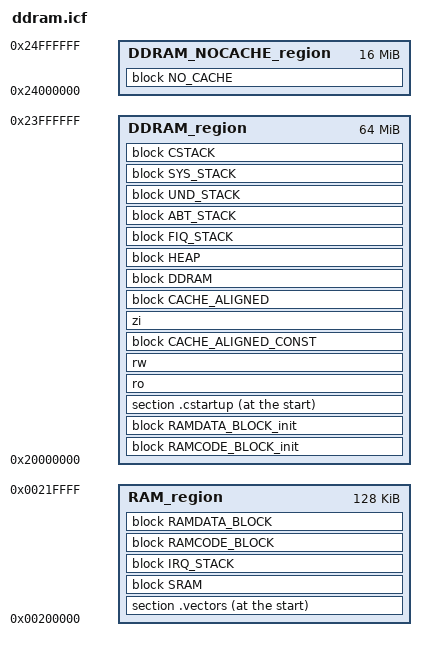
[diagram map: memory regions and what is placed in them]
define memory mem with size = 4G;
define region RAM_region           = mem:[from 0x00200000 to 0x0021FFFF];
define region DDRAM_region         = mem:[from 0x20000000 to 0x23FFFFFF];
define region DDRAM_NOCACHE_region = mem:[from 0x24000000 to 0x24FFFFFF];

define block CSTACK    with alignment = 8, size = 0x800 { };
define block IRQ_STACK with alignment = 8, size = 0x60  { };
define block FIQ_STACK with alignment = 8, size = 0x60  { };
define block ABT_STACK with alignment = 8, size = 0x40  { };
define block UND_STACK with alignment = 8, size = 0x40  { };
define block SYS_STACK with alignment = 8, size = 0x40  { };
define block HEAP      with alignment = 4, size = 0x200 { };

define block SRAM { section .region_sram  };
define block DDRAM { section .region_ddr };

define block RAMCODE_BLOCK      { section .ramcode_section };
define block RAMCODE_BLOCK_init { section .ramcode_section_init };
define block RAMDATA_BLOCK      { section .ramdata_section };
define block RAMDATA_BLOCK_init { section .ramdata_section_init };

/* Please see drivers/mm/cache.h for details on the "Cache-aligned" sections */
define block NO_CACHE { section .region_nocache };
define block CACHE_ALIGNED with alignment = 32 { section .region_cache_aligned };
define block CACHE_ALIGNED_CONST with alignment = 32 { section .region_cache_aligned_const };

initialize by copy with packing=none { section .vectors };
do not initialize { section .region_sram };
do not initialize { section .region_ddr };
do not initialize { section .region_nocache };
do not initialize { section .region_cache_aligned };
initialize manually { section .ramcode_section };
initialize manually { section .ramdata_section };

place at start of RAM_region { section .vectors };
place in RAM_region { block SRAM };
place in RAM_region { block IRQ_STACK };
place in RAM_region { block RAMCODE_BLOCK };
place in DDRAM_region   { block RAMCODE_BLOCK_init };
place in RAM_region { block RAMDATA_BLOCK };
place in DDRAM_region   { block RAMDATA_BLOCK_init };

place at start of DDRAM_region { section .cstartup };
place in DDRAM_region { ro };
place in DDRAM_region { rw };
place in DDRAM_region { block CACHE_ALIGNED_CONST };
place in DDRAM_region { zi };
place in DDRAM_region { block CACHE_ALIGNED };
place in DDRAM_region { block DDRAM };
place in DDRAM_region { block HEAP };
place in DDRAM_region { block FIQ_STACK };
place in DDRAM_region { block ABT_STACK };
place in DDRAM_region { block UND_STACK };
place in DDRAM_region { block SYS_STACK };
place in DDRAM_region { block CSTACK };

place in DDRAM_NOCACHE_region { block NO_CACHE };
